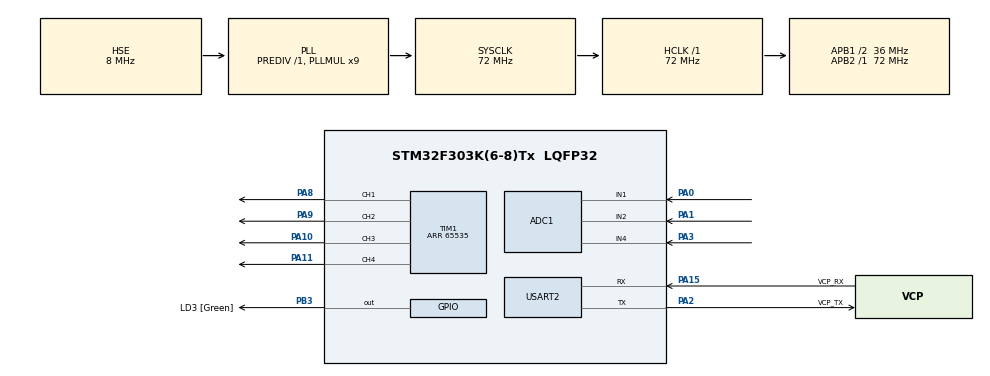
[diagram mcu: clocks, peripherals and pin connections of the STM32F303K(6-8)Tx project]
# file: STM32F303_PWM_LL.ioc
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ADC1.ClockPrescaler=ADC_CLOCK_SYNC_PCLK_DIV1
ADC1.DiscontinuousConvMode=DISABLE
ADC1.EnableRegularConversion=DISABLE
ADC1.ExternalTrigInjecConv=ADC_EXTERNALTRIGINJECCONV_T1_TRGO2
ADC1.InjNumberOfConversion=3
ADC1.InjectedChannel-1\#ChannelInjectedConversion=ADC_CHANNEL_1
ADC1.InjectedChannel-2\#ChannelInjectedConversion=ADC_CHANNEL_2
ADC1.InjectedChannel-3\#ChannelInjectedConversion=ADC_CHANNEL_4
ADC1.InjectedConvMode=None
ADC1.InjectedOffset-1\#ChannelInjectedConversion=0
ADC1.InjectedOffset-2\#ChannelInjectedConversion=0
ADC1.InjectedOffset-3\#ChannelInjectedConversion=0
ADC1.InjectedOffsetNumber-1\#ChannelInjectedConversion=ADC_OFFSET_NONE
ADC1.InjectedOffsetNumber-2\#ChannelInjectedConversion=ADC_OFFSET_NONE
ADC1.InjectedOffsetNumber-3\#ChannelInjectedConversion=ADC_OFFSET_NONE
ADC1.InjectedRank-1\#ChannelInjectedConversion=1
ADC1.InjectedRank-2\#ChannelInjectedConversion=2
ADC1.InjectedRank-3\#ChannelInjectedConversion=3
ADC1.InjectedSamplingTime-1\#ChannelInjectedConversion=ADC_SAMPLETIME_7CYCLES_5
ADC1.InjectedSamplingTime-2\#ChannelInjectedConversion=ADC_SAMPLETIME_7CYCLES_5
ADC1.InjectedSamplingTime-3\#ChannelInjectedConversion=ADC_SAMPLETIME_7CYCLES_5
ADC1.QueueInjectedContext=DISABLE
ADC1.SubFamily=STM32F303x8
ADC1.master=1
Mcu.Family=STM32F3
Mcu.Name=STM32F303K(6-8)Tx
Mcu.Package=LQFP32
NVIC.ADC1_2_IRQn=true\:0\:0\:false\:false\:true\:true\:true
NVIC.PriorityGroup=NVIC_PRIORITYGROUP_4
NVIC.TIM1_UP_TIM16_IRQn=true\:0\:0\:false\:false\:true\:true\:true
PA0.Mode=IN1-Single-Ended
PA0.Signal=ADC1_IN1
PA1.Mode=IN2-Single-Ended
PA1.Signal=ADC1_IN2
PA10.Signal=S_TIM1_CH3
PA11.Signal=S_TIM1_CH4
PA13.GPIO_Label=SWDIO
PA13.Mode=Serial_Wire
PA13.Signal=SYS_JTMS-SWDIO
PA14.GPIO_Label=SWCLK
PA14.Mode=Serial_Wire
PA14.Signal=SYS_JTCK-SWCLK
PA15.GPIO_Label=VCP_RX
PA15.Mode=Asynchronous
PA15.Signal=USART2_RX
PA2.GPIO_Label=VCP_TX
PA2.Mode=Asynchronous
PA2.Signal=USART2_TX
PA3.Mode=IN4-Single-Ended
PA3.Signal=ADC1_IN4
PA8.Signal=S_TIM1_CH1
PA9.Signal=S_TIM1_CH2
PB3.GPIO_Label=LD3 [Green]
PB3.Signal=GPIO_Output
PF0\ /\ OSC_IN.GPIO_Label=MCO
PF0\ /\ OSC_IN.Mode=HSE-External-Clock-Source
PF0\ /\ OSC_IN.Signal=RCC_OSC_IN
ProjectManager.HeapSize=0x200
ProjectManager.StackSize=0x400
ProjectManager.TargetToolchain=STM32CubeIDE
RCC.AHBFreq_Value=72000000
RCC.APB1CLKDivider=RCC_HCLK_DIV2
RCC.APB1Freq_Value=36000000
RCC.APB1TimFreq_Value=72000000
RCC.APB2Freq_Value=72000000
RCC.APB2TimFreq_Value=72000000
RCC.CortexFreq_Value=72000000
RCC.HCLKFreq_Value=72000000
RCC.HSE_VALUE=8000000
RCC.HSI_VALUE=8000000
RCC.PLLMUL=RCC_PLL_MUL9
RCC.PLLSourceVirtual=RCC_PLLSOURCE_HSE
RCC.SYSCLKFreq_VALUE=72000000
RCC.SYSCLKSourceVirtual=RCC_SYSCLKSOURCE_PLLCLK
SH.S_TIM1_CH1.0=TIM1_CH1,PWM Generation1 CH1
SH.S_TIM1_CH2.0=TIM1_CH2,PWM Generation2 CH2
SH.S_TIM1_CH3.0=TIM1_CH3,PWM Generation3 CH3
SH.S_TIM1_CH4.0=TIM1_CH4,PWM Generation4 CH4
TIM1.AutoReloadPreload=TIM_AUTORELOAD_PRELOAD_DISABLE
TIM1.Channel-PWM\ Generation1\ CH1=TIM_CHANNEL_1
TIM1.Channel-PWM\ Generation2\ CH2=TIM_CHANNEL_2
TIM1.Channel-PWM\ Generation3\ CH3=TIM_CHANNEL_3
TIM1.Channel-PWM\ Generation4\ CH4=TIM_CHANNEL_4
TIM1.Period=65535
TIM1.Pulse-PWM\ Generation1\ CH1=10000
TIM1.Pulse-PWM\ Generation4\ CH4=65530
TIM1.TIM_MasterOutputTrigger=TIM_TRGO_UPDATE
TIM1.TIM_MasterOutputTrigger2=TIM_TRGO2_OC4REF
USART2.VirtualMode-Asynchronous=VM_ASYNC
VP_TIM1_VS_ClockSourceINT.Mode=Internal
board=NUCLEO-F303K8

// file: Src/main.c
/* USER CODE BEGIN Header */
/**
  ******************************************************************************
  * @file           : main.c
  * @brief          : Main program body
  ******************************************************************************
  * @attention
  *
  * <h2><center>&copy; Copyright (c) 2019 STMicroelectronics.
  * All rights reserved.</center></h2>
  *
  * This software component is licensed by ST under BSD 3-Clause license,
  * the "License"; You may not use this file except in compliance with the
  * License. You may obtain a copy of the License at:
  *                        opensource.org/licenses/BSD-3-Clause
  *
  ******************************************************************************
  */
/* USER CODE END Header */

#include "main.h"
#include "adc.h"
#include "tim.h"
#include "usart.h"
#include "gpio.h"

/* USER CODE BEGIN Includes */
#include "Wrapper.hpp"
/* USER CODE END Includes */

void SystemClock_Config(void);

int main(void)
{

  /* MCU Configuration--------------------------------------------------------*/

  /* Reset of all peripherals, Initializes the Flash interface and the Systick. */
  HAL_Init();

  /* Configure the system clock */
  SystemClock_Config();

  /* Initialize all configured peripherals */
  MX_GPIO_Init();
  MX_USART2_UART_Init();
  MX_TIM1_Init();
  MX_ADC1_Init();
  /* USER CODE BEGIN 2 */
  CPP_Wrapper();
  /* USER CODE END 2 */

  /* Infinite loop */
  while (1)
  {

  }
}

void SystemClock_Config(void)
{
  RCC_OscInitTypeDef RCC_OscInitStruct = {0};
  RCC_ClkInitTypeDef RCC_ClkInitStruct = {0};
  RCC_PeriphCLKInitTypeDef PeriphClkInit = {0};

  /** Initializes the CPU, AHB and APB busses clocks
  */
  RCC_OscInitStruct.OscillatorType = RCC_OSCILLATORTYPE_HSE;
  RCC_OscInitStruct.HSEState = RCC_HSE_BYPASS;
  RCC_OscInitStruct.HSEPredivValue = RCC_HSE_PREDIV_DIV1;
  RCC_OscInitStruct.HSIState = RCC_HSI_ON;
  RCC_OscInitStruct.PLL.PLLState = RCC_PLL_ON;
  RCC_OscInitStruct.PLL.PLLSource = RCC_PLLSOURCE_HSE;
  RCC_OscInitStruct.PLL.PLLMUL = RCC_PLL_MUL9;
  if (HAL_RCC_OscConfig(&RCC_OscInitStruct) != HAL_OK)
  {
    Error_Handler();
  }
  /** Initializes the CPU, AHB and APB busses clocks
  */
  RCC_ClkInitStruct.ClockType = RCC_CLOCKTYPE_HCLK|RCC_CLOCKTYPE_SYSCLK
                              |RCC_CLOCKTYPE_PCLK1|RCC_CLOCKTYPE_PCLK2;
  RCC_ClkInitStruct.SYSCLKSource = RCC_SYSCLKSOURCE_PLLCLK;
  RCC_ClkInitStruct.AHBCLKDivider = RCC_SYSCLK_DIV1;
  RCC_ClkInitStruct.APB1CLKDivider = RCC_HCLK_DIV2;
  RCC_ClkInitStruct.APB2CLKDivider = RCC_HCLK_DIV1;

  if (HAL_RCC_ClockConfig(&RCC_ClkInitStruct, FLASH_LATENCY_2) != HAL_OK)
  {
    Error_Handler();
  }
  PeriphClkInit.PeriphClockSelection = RCC_PERIPHCLK_TIM1;
  PeriphClkInit.Tim1ClockSelection = RCC_TIM1CLK_HCLK;
  if (HAL_RCCEx_PeriphCLKConfig(&PeriphClkInit) != HAL_OK)
  {
    Error_Handler();
  }
}

void Error_Handler(void)
{
}

/************************ (C) COPYRIGHT STMicroelectronics *****END OF FILE****/
